# SRAM4MB register map
Registers from a debugger description file.
Registers are 32-bit, access not given, no defined reset value unless marked. A register's access mark holds for its fields unless they carry their own. Addresses are absolute; registers are grouped by the start of their names; lines under a group give offsets from that group; [hi:lo] are bit positions; {n}, {i} and the like mark numbered series; 'fields as' and 'values as' point back to an identical list; <NAME> marks a mode.

## SFR
0x80400000 SR4PCMD
  [0] PROTREL
0x80400100 SR4EDC
  [0] ECC_ENABLE
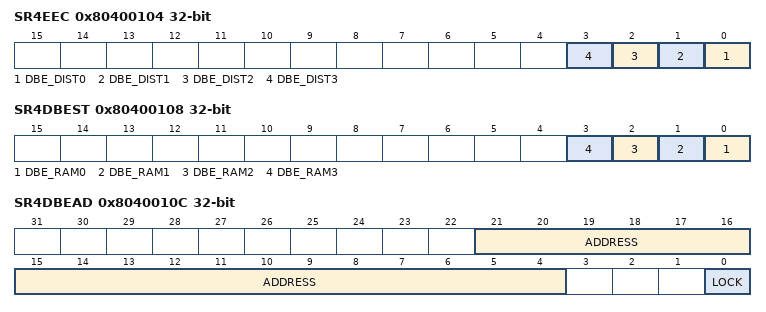
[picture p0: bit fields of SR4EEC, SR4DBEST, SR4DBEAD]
0x80400104 SR4EEC
  [n] DBE_DIST{n} (n=0..3)
0x80400108 SR4DBEST ro
  [n] DBE_RAM{n} (n=0..3)
0x8040010C SR4DBEAD ro
  [21:4] ADDRESS, [0] LOCK
0x80400110 SR4DBECNT ro
  [3:0] ERRCOUNT
